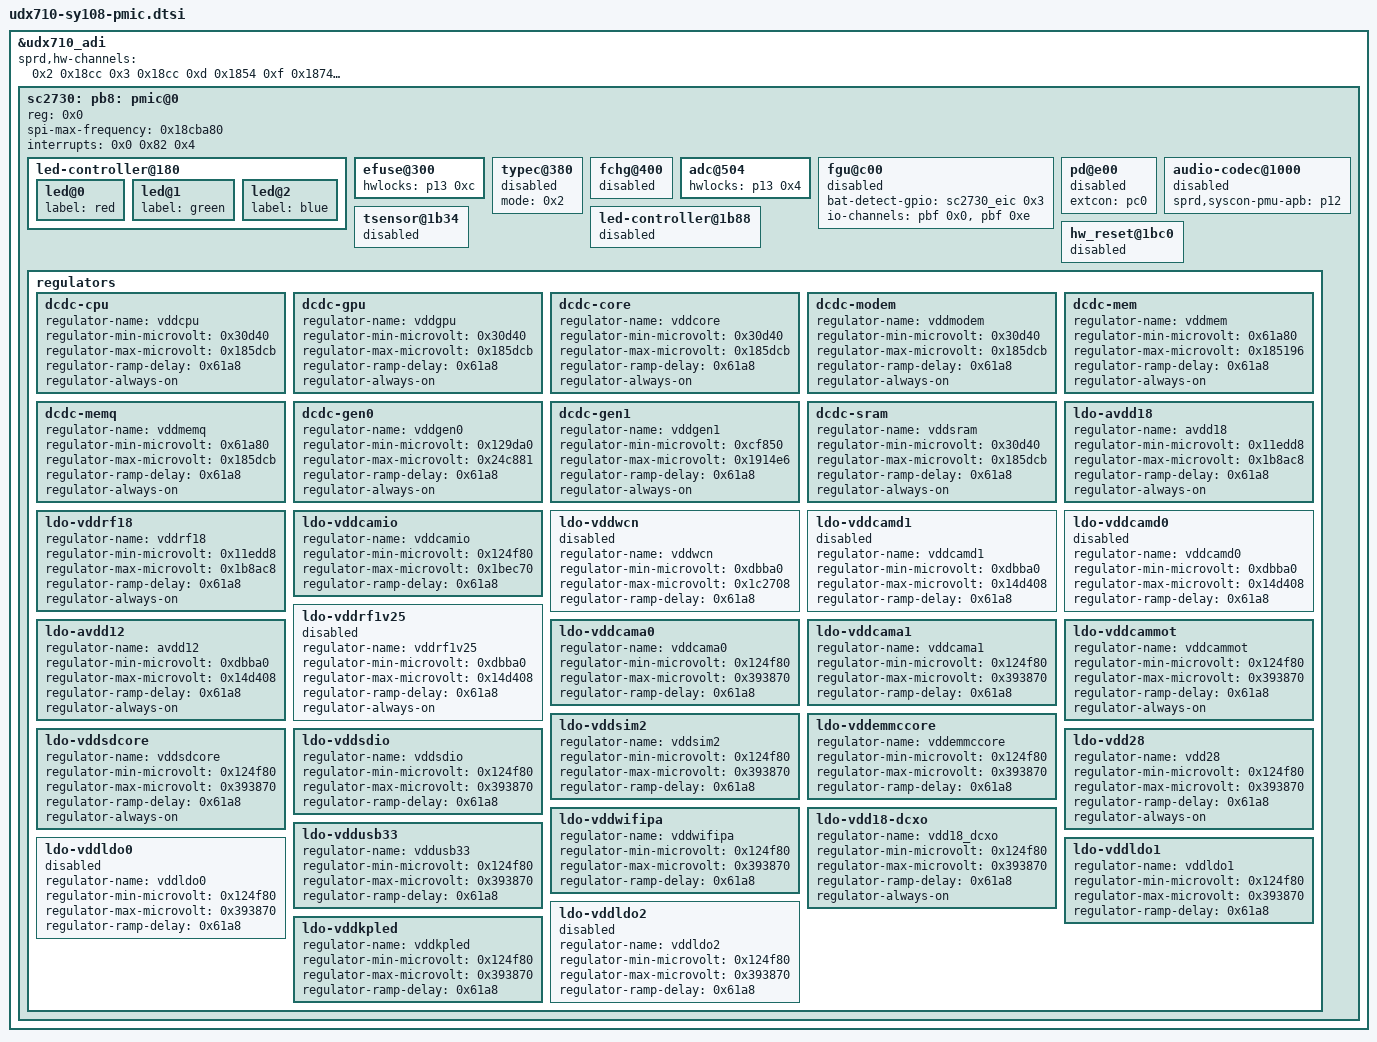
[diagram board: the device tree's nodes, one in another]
// SPDX-License-Identifier: GPL-2.0-only
/* 4H10 board: SC2730 placement, wiring, enabled functions and rail policy. */
&udx710_adi {
	status = "okay";
	sprd,hw-channels = <0x2 0x18cc 0x3 0x18cc 0xd 0x1854 0xf 0x1874 0x11 0x1844 0x13 0x1844 0x1e 0x1820 0x1f 0x197c 0x20 0x197c 0x21 0x1988 0x23 0x19b8 0x27 0x19ac>;
	sc2730: pb8: pmic@0 {
		reg = <0x0>;
		spi-max-frequency = <0x18cba80>;
		interrupts = <0x0 0x82 0x4>;
		phandle = <0xb8>;
#include "sc2730.dtsi"
	};
};

&sc2730 {
	led-controller@180 {
		led@0 {
			label = "red";
		};
		led@1 {
			label = "green";
		};
		led@2 {
			label = "blue";
		};
	};
	efuse@300 {
		hwlocks = <&p13 0xc>;
	};
	typec@380 {
		mode = <0x2>;
		status = "disabled";
	};
	fchg@400 {
		status = "disabled";
	};
	adc@504 {
		hwlocks = <&p13 0x4>;
	};
	fgu@c00 {
		bat-detect-gpio = <&sc2730_eic 0x3 0x0>;
		io-channels = <&pbf 0x0 &pbf 0xe>;
		io-channel-names = "bat-temp", "charge-vol";
		status = "disabled";
	};
	pd@e00 {
		extcon = <&pc0>;
		status = "disabled";
	};
	audio-codec@1000 {
		sprd,syscon-pmu-apb = <&p12>;
		status = "disabled";
	};
	tsensor@1b34 {
		status = "disabled";
	};
	led-controller@1b88 {
		status = "disabled";
	};
	hw_reset@1bc0 {
		status = "disabled";
	};
	regulators {
		dcdc-cpu {
			regulator-name = "vddcpu";
			regulator-min-microvolt = <0x30d40>;
			regulator-max-microvolt = <0x185dcb>;
			regulator-ramp-delay = <0x61a8>;
			regulator-always-on;
		};
		dcdc-gpu {
			regulator-name = "vddgpu";
			regulator-min-microvolt = <0x30d40>;
			regulator-max-microvolt = <0x185dcb>;
			regulator-ramp-delay = <0x61a8>;
			regulator-always-on;
		};
		dcdc-core {
			regulator-name = "vddcore";
			regulator-min-microvolt = <0x30d40>;
			regulator-max-microvolt = <0x185dcb>;
			regulator-ramp-delay = <0x61a8>;
			regulator-always-on;
		};
		dcdc-modem {
			regulator-name = "vddmodem";
			regulator-min-microvolt = <0x30d40>;
			regulator-max-microvolt = <0x185dcb>;
			regulator-ramp-delay = <0x61a8>;
			regulator-always-on;
		};
		dcdc-mem {
			regulator-name = "vddmem";
			regulator-min-microvolt = <0x61a80>;
			regulator-max-microvolt = <0x185196>;
			regulator-ramp-delay = <0x61a8>;
			regulator-always-on;
		};
		dcdc-memq {
			regulator-name = "vddmemq";
			regulator-min-microvolt = <0x61a80>;
			regulator-max-microvolt = <0x185dcb>;
			regulator-ramp-delay = <0x61a8>;
			regulator-always-on;
		};
		dcdc-gen0 {
			regulator-name = "vddgen0";
			regulator-min-microvolt = <0x129da0>;
			regulator-max-microvolt = <0x24c881>;
			regulator-ramp-delay = <0x61a8>;
			regulator-always-on;
		};
		dcdc-gen1 {
			regulator-name = "vddgen1";
			regulator-min-microvolt = <0xcf850>;
			regulator-max-microvolt = <0x1914e6>;
			regulator-ramp-delay = <0x61a8>;
			regulator-always-on;
		};
		dcdc-sram {
			regulator-name = "vddsram";
			regulator-min-microvolt = <0x30d40>;
			regulator-max-microvolt = <0x185dcb>;
			regulator-ramp-delay = <0x61a8>;
			regulator-always-on;
		};
		ldo-avdd18 {
			regulator-name = "avdd18";
			regulator-min-microvolt = <0x11edd8>;
			regulator-max-microvolt = <0x1b8ac8>;
			regulator-ramp-delay = <0x61a8>;
			regulator-always-on;
		};
		ldo-vddrf18 {
			regulator-name = "vddrf18";
			regulator-min-microvolt = <0x11edd8>;
			regulator-max-microvolt = <0x1b8ac8>;
			regulator-ramp-delay = <0x61a8>;
			regulator-always-on;
			status = "okay";
		};
		ldo-vddcamio {
			regulator-name = "vddcamio";
			regulator-min-microvolt = <0x124f80>;
			regulator-max-microvolt = <0x1bec70>;
			regulator-ramp-delay = <0x61a8>;
		};
		ldo-vddwcn {
			regulator-name = "vddwcn";
			regulator-min-microvolt = <0xdbba0>;
			regulator-max-microvolt = <0x1c2708>;
			regulator-ramp-delay = <0x61a8>;
			status = "disabled";
		};
		ldo-vddcamd1 {
			regulator-name = "vddcamd1";
			regulator-min-microvolt = <0xdbba0>;
			regulator-max-microvolt = <0x14d408>;
			regulator-ramp-delay = <0x61a8>;
			status = "disabled";
		};
		ldo-vddcamd0 {
			regulator-name = "vddcamd0";
			regulator-min-microvolt = <0xdbba0>;
			regulator-max-microvolt = <0x14d408>;
			regulator-ramp-delay = <0x61a8>;
			status = "disabled";
		};
		ldo-vddrf1v25 {
			regulator-name = "vddrf1v25";
			regulator-min-microvolt = <0xdbba0>;
			regulator-max-microvolt = <0x14d408>;
			regulator-ramp-delay = <0x61a8>;
			regulator-always-on;
			status = "disabled";
		};
		ldo-avdd12 {
			regulator-name = "avdd12";
			regulator-min-microvolt = <0xdbba0>;
			regulator-max-microvolt = <0x14d408>;
			regulator-ramp-delay = <0x61a8>;
			regulator-always-on;
		};
		ldo-vddcama0 {
			regulator-name = "vddcama0";
			regulator-min-microvolt = <0x124f80>;
			regulator-max-microvolt = <0x393870>;
			regulator-ramp-delay = <0x61a8>;
		};
		ldo-vddcama1 {
			regulator-name = "vddcama1";
			regulator-min-microvolt = <0x124f80>;
			regulator-max-microvolt = <0x393870>;
			regulator-ramp-delay = <0x61a8>;
		};
		ldo-vddcammot {
			regulator-name = "vddcammot";
			regulator-min-microvolt = <0x124f80>;
			regulator-max-microvolt = <0x393870>;
			regulator-ramp-delay = <0x61a8>;
			/* Already enabled by board firmware. Its board consumer is not
			 * described yet; retain this rail explicitly, not every rail. */
			regulator-always-on;
			status = "okay";
		};
		ldo-vddsim2 {
			regulator-name = "vddsim2";
			regulator-min-microvolt = <0x124f80>;
			regulator-max-microvolt = <0x393870>;
			regulator-ramp-delay = <0x61a8>;
		};
		ldo-vddemmccore {
			regulator-name = "vddemmccore";
			regulator-min-microvolt = <0x124f80>;
			regulator-max-microvolt = <0x393870>;
			regulator-ramp-delay = <0x61a8>;
		};
		ldo-vddsdcore {
			regulator-name = "vddsdcore";
			regulator-min-microvolt = <0x124f80>;
			regulator-max-microvolt = <0x393870>;
			regulator-ramp-delay = <0x61a8>;
			regulator-always-on;
		};
		ldo-vddsdio {
			regulator-name = "vddsdio";
			regulator-min-microvolt = <0x124f80>;
			regulator-max-microvolt = <0x393870>;
			regulator-ramp-delay = <0x61a8>;
		};
		ldo-vdd28 {
			regulator-name = "vdd28";
			regulator-min-microvolt = <0x124f80>;
			regulator-max-microvolt = <0x393870>;
			regulator-ramp-delay = <0x61a8>;
			regulator-always-on;
		};
		ldo-vddwifipa {
			regulator-name = "vddwifipa";
			regulator-min-microvolt = <0x124f80>;
			regulator-max-microvolt = <0x393870>;
			regulator-ramp-delay = <0x61a8>;
		};
		ldo-vdd18-dcxo {
			regulator-name = "vdd18_dcxo";
			regulator-min-microvolt = <0x124f80>;
			regulator-max-microvolt = <0x393870>;
			regulator-ramp-delay = <0x61a8>;
			regulator-always-on;
		};
		ldo-vddusb33 {
			regulator-name = "vddusb33";
			regulator-min-microvolt = <0x124f80>;
			regulator-max-microvolt = <0x393870>;
			regulator-ramp-delay = <0x61a8>;
		};
		ldo-vddldo0 {
			regulator-name = "vddldo0";
			regulator-min-microvolt = <0x124f80>;
			regulator-max-microvolt = <0x393870>;
			regulator-ramp-delay = <0x61a8>;
			status = "disabled";
		};
		ldo-vddldo1 {
			regulator-name = "vddldo1";
			regulator-min-microvolt = <0x124f80>;
			regulator-max-microvolt = <0x393870>;
			regulator-ramp-delay = <0x61a8>;
		};
		ldo-vddldo2 {
			regulator-name = "vddldo2";
			regulator-min-microvolt = <0x124f80>;
			regulator-max-microvolt = <0x393870>;
			regulator-ramp-delay = <0x61a8>;
			status = "disabled";
		};
		ldo-vddkpled {
			regulator-name = "vddkpled";
			regulator-min-microvolt = <0x124f80>;
			regulator-max-microvolt = <0x393870>;
			regulator-ramp-delay = <0x61a8>;
		};
	};
};
